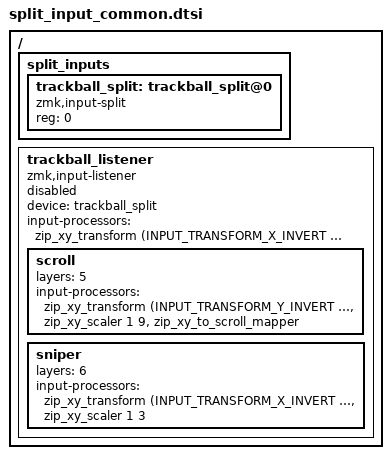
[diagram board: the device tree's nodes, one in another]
#include <dt-bindings/zmk/input_transform.h>
#include <input/processors.dtsi>

/ {
  split_inputs {
    #address-cells = <1>;
    #size-cells = <0>;

    trackball_split: trackball_split@0 {
      compatible = "zmk,input-split";
      reg = <0>;
    };
  };

  trackball_listener: trackball_listener {
    compatible = "zmk,input-listener";
    status = "disabled";
    device = <&trackball_split>;
    input-processors = <&zip_xy_transform (INPUT_TRANSFORM_X_INVERT | INPUT_TRANSFORM_Y_INVERT | INPUT_TRANSFORM_XY_SWAP )>;
    scroll {
      layers = <5>;
      input-processors = <&zip_xy_transform (INPUT_TRANSFORM_Y_INVERT | INPUT_TRANSFORM_XY_SWAP)>, <&zip_xy_scaler 1 9>, <&zip_xy_to_scroll_mapper>;
    };
    sniper {
      layers = <6>;
      input-processors = <&zip_xy_transform (INPUT_TRANSFORM_X_INVERT | INPUT_TRANSFORM_Y_INVERT | INPUT_TRANSFORM_XY_SWAP )>, <&zip_xy_scaler 1 3>;
    };
  };
};
